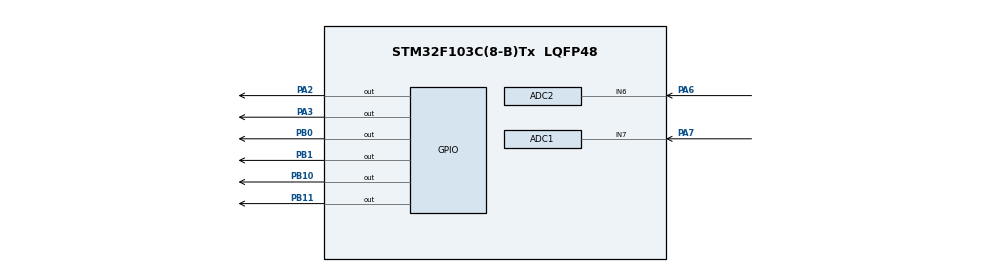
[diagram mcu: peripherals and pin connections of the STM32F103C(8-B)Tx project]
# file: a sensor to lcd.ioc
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ADC1.Channel-0\#ChannelRegularConversion=ADC_CHANNEL_7
ADC1.ContinuousConvMode=ENABLE
ADC1.NbrOfConversionFlag=1
ADC1.Rank-0\#ChannelRegularConversion=1
ADC1.SamplingTime-0\#ChannelRegularConversion=ADC_SAMPLETIME_1CYCLE_5
ADC1.master=1
ADC2.Channel-0\#ChannelRegularConversion=ADC_CHANNEL_6
ADC2.ContinuousConvMode=ENABLE
ADC2.NbrOfConversionFlag=1
ADC2.Rank-0\#ChannelRegularConversion=1
ADC2.SamplingTime-0\#ChannelRegularConversion=ADC_SAMPLETIME_1CYCLE_5
Mcu.Family=STM32F1
Mcu.Name=STM32F103C(8-B)Tx
Mcu.Package=LQFP48
NVIC.PriorityGroup=NVIC_PRIORITYGROUP_4
PA13.Mode=Serial_Wire
PA13.Signal=SYS_JTMS-SWDIO
PA14.Mode=Serial_Wire
PA14.Signal=SYS_JTCK-SWCLK
PA2.GPIO_Speed=GPIO_SPEED_FREQ_HIGH
PA2.Signal=GPIO_Output
PA3.GPIO_Speed=GPIO_SPEED_FREQ_HIGH
PA3.Signal=GPIO_Output
PA6.Signal=ADCx_IN6
PA7.Signal=ADCx_IN7
PB0.GPIO_Speed=GPIO_SPEED_FREQ_HIGH
PB0.Signal=GPIO_Output
PB1.GPIO_Speed=GPIO_SPEED_FREQ_HIGH
PB1.Signal=GPIO_Output
PB10.GPIO_Speed=GPIO_SPEED_FREQ_HIGH
PB10.Signal=GPIO_Output
PB11.GPIO_Speed=GPIO_SPEED_FREQ_HIGH
PB11.Signal=GPIO_Output
ProjectManager.HeapSize=0x200
ProjectManager.StackSize=0x400
ProjectManager.TargetToolchain=STM32CubeIDE
RCC.APB1Freq_Value=8000000
RCC.APB2Freq_Value=8000000
SH.ADCx_IN6.0=ADC2_IN6,IN6
SH.ADCx_IN7.0=ADC1_IN7,IN7
board=custom

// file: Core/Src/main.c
/* USER CODE BEGIN Header */
/**
  ******************************************************************************
  * @file           : main.c
  * @brief          : Main program body
  ******************************************************************************
  * @attention
  *
  * <h2><center>&copy; Copyright (c) 2021 STMicroelectronics.
  * All rights reserved.</center></h2>
  *
  * This software component is licensed by ST under BSD 3-Clause license,
  * the "License"; You may not use this file except in compliance with the
  * License. You may obtain a copy of the License at:
  *                        opensource.org/licenses/BSD-3-Clause
  *
  ******************************************************************************
  */
/* USER CODE END Header */
#include "main.h"
#include "lcd.h"

ADC_HandleTypeDef hadc1;
ADC_HandleTypeDef hadc2;

/* USER CODE BEGIN PV */
uint16_t moisture_value;
uint16_t vibrating_value;
int a=0;
/* USER CODE END PV */

void SystemClock_Config(void);
static void MX_GPIO_Init(void);
static void MX_ADC1_Init(void);
static void MX_ADC2_Init(void);

int main(void)
{

  /* MCU Configuration--------------------------------------------------------*/

  /* Reset of all peripherals, Initializes the Flash interface and the Systick. */
  HAL_Init();

  /* Configure the system clock */
  SystemClock_Config();

  /* Initialize all configured peripherals */
  MX_GPIO_Init();
  MX_ADC1_Init();
  MX_ADC2_Init();
  /* USER CODE BEGIN 2 */
  HAL_ADC_Start(&hadc1);
  HAL_ADC_Start(&hadc2);
  Lcd_PortType ports[] = { GPIOB, GPIOB, GPIOB, GPIOB };
  Lcd_PinType pins[] = {GPIO_PIN_0, GPIO_PIN_1, GPIO_PIN_10, GPIO_PIN_11};
  Lcd_HandleTypeDef lcd;
  lcd = Lcd_create(ports, pins, GPIOA, GPIO_PIN_2, GPIOA, GPIO_PIN_3, LCD_4_BIT_MODE);
  Lcd_cursor(&lcd, 0,2);
  Lcd_string(&lcd, "MOI_SEN:");
  Lcd_cursor(&lcd, 1,2);
  Lcd_string(&lcd, "VIB_SEN:");
  HAL_Delay(500);
  /* USER CODE END 2 */

  /* Infinite loop */
  while (1)
  {
 HAL_ADC_PollForConversion(&hadc1,1000);
 moisture_value=4095-HAL_ADC_GetValue(&hadc1);
 HAL_ADC_PollForConversion(&hadc2,1000);
 vibrating_value =HAL_ADC_GetValue(&hadc2);
 HAL_Delay(100);
 Lcd_cursor(&lcd, 0,10);
 Lcd_int(&lcd, moisture_value);
 Lcd_cursor(&lcd, 1,10);
 Lcd_int(&lcd, vibrating_value);

  }
}

void SystemClock_Config(void)
{
  RCC_OscInitTypeDef RCC_OscInitStruct = {0};
  RCC_ClkInitTypeDef RCC_ClkInitStruct = {0};
  RCC_PeriphCLKInitTypeDef PeriphClkInit = {0};

  /** Initializes the RCC Oscillators according to the specified parameters
  * in the RCC_OscInitTypeDef structure.
  */
  RCC_OscInitStruct.OscillatorType = RCC_OSCILLATORTYPE_HSI;
  RCC_OscInitStruct.HSIState = RCC_HSI_ON;
  RCC_OscInitStruct.HSICalibrationValue = RCC_HSICALIBRATION_DEFAULT;
  RCC_OscInitStruct.PLL.PLLState = RCC_PLL_NONE;
  if (HAL_RCC_OscConfig(&RCC_OscInitStruct) != HAL_OK)
  {
    Error_Handler();
  }
  /** Initializes the CPU, AHB and APB buses clocks
  */
  RCC_ClkInitStruct.ClockType = RCC_CLOCKTYPE_HCLK|RCC_CLOCKTYPE_SYSCLK
                              |RCC_CLOCKTYPE_PCLK1|RCC_CLOCKTYPE_PCLK2;
  RCC_ClkInitStruct.SYSCLKSource = RCC_SYSCLKSOURCE_HSI;
  RCC_ClkInitStruct.AHBCLKDivider = RCC_SYSCLK_DIV1;
  RCC_ClkInitStruct.APB1CLKDivider = RCC_HCLK_DIV1;
  RCC_ClkInitStruct.APB2CLKDivider = RCC_HCLK_DIV1;

  if (HAL_RCC_ClockConfig(&RCC_ClkInitStruct, FLASH_LATENCY_0) != HAL_OK)
  {
    Error_Handler();
  }
  PeriphClkInit.PeriphClockSelection = RCC_PERIPHCLK_ADC;
  PeriphClkInit.AdcClockSelection = RCC_ADCPCLK2_DIV2;
  if (HAL_RCCEx_PeriphCLKConfig(&PeriphClkInit) != HAL_OK)
  {
    Error_Handler();
  }
}

static void MX_ADC1_Init(void)
{

  ADC_ChannelConfTypeDef sConfig = {0};

  /** Common config
  */
  hadc1.Instance = ADC1;
  hadc1.Init.ScanConvMode = ADC_SCAN_DISABLE;
  hadc1.Init.ContinuousConvMode = ENABLE;
  hadc1.Init.DiscontinuousConvMode = DISABLE;
  hadc1.Init.ExternalTrigConv = ADC_SOFTWARE_START;
  hadc1.Init.DataAlign = ADC_DATAALIGN_RIGHT;
  hadc1.Init.NbrOfConversion = 1;
  if (HAL_ADC_Init(&hadc1) != HAL_OK)
  {
    Error_Handler();
  }
  /** Configure Regular Channel
  */
  sConfig.Channel = ADC_CHANNEL_4;
  sConfig.Rank = ADC_REGULAR_RANK_1;
  sConfig.SamplingTime = ADC_SAMPLETIME_1CYCLE_5;
  if (HAL_ADC_ConfigChannel(&hadc1, &sConfig) != HAL_OK)
  {
    Error_Handler();
  }

}

static void MX_ADC2_Init(void)
{

  ADC_ChannelConfTypeDef sConfig = {0};

  /** Common config
  */
  hadc2.Instance = ADC2;
  hadc2.Init.ScanConvMode = ADC_SCAN_DISABLE;
  hadc2.Init.ContinuousConvMode = ENABLE;
  hadc2.Init.DiscontinuousConvMode = DISABLE;
  hadc2.Init.ExternalTrigConv = ADC_SOFTWARE_START;
  hadc2.Init.DataAlign = ADC_DATAALIGN_RIGHT;
  hadc2.Init.NbrOfConversion = 1;
  if (HAL_ADC_Init(&hadc2) != HAL_OK)
  {
    Error_Handler();
  }
  /** Configure Regular Channel
  */
  sConfig.Channel = ADC_CHANNEL_5;
  sConfig.Rank = ADC_REGULAR_RANK_1;
  sConfig.SamplingTime = ADC_SAMPLETIME_1CYCLE_5;
  if (HAL_ADC_ConfigChannel(&hadc2, &sConfig) != HAL_OK)
  {
    Error_Handler();
  }

}

static void MX_GPIO_Init(void)
{
  GPIO_InitTypeDef GPIO_InitStruct = {0};

  /* GPIO Ports Clock Enable */
  __HAL_RCC_GPIOA_CLK_ENABLE();
  __HAL_RCC_GPIOB_CLK_ENABLE();

  /*Configure GPIO pin Output Level */
  HAL_GPIO_WritePin(GPIOA, GPIO_PIN_2|GPIO_PIN_3, GPIO_PIN_RESET);

  /*Configure GPIO pin Output Level */
  HAL_GPIO_WritePin(GPIOB, GPIO_PIN_0|GPIO_PIN_1|GPIO_PIN_10|GPIO_PIN_11
                          |GPIO_PIN_5, GPIO_PIN_RESET);

  /*Configure GPIO pins : PA2 PA3 */
  GPIO_InitStruct.Pin = GPIO_PIN_2|GPIO_PIN_3;
  GPIO_InitStruct.Mode = GPIO_MODE_OUTPUT_PP;
  GPIO_InitStruct.Pull = GPIO_NOPULL;
  GPIO_InitStruct.Speed = GPIO_SPEED_FREQ_HIGH;
  HAL_GPIO_Init(GPIOA, &GPIO_InitStruct);

  /*Configure GPIO pins : PB0 PB1 PB10 PB11
                           PB5 */
  GPIO_InitStruct.Pin = GPIO_PIN_0|GPIO_PIN_1|GPIO_PIN_10|GPIO_PIN_11
                          |GPIO_PIN_5;
  GPIO_InitStruct.Mode = GPIO_MODE_OUTPUT_PP;
  GPIO_InitStruct.Pull = GPIO_NOPULL;
  GPIO_InitStruct.Speed = GPIO_SPEED_FREQ_HIGH;
  HAL_GPIO_Init(GPIOB, &GPIO_InitStruct);

}

void Error_Handler(void)
{
  __disable_irq();
  while (1)
  {
  }
}

/************************ (C) COPYRIGHT STMicroelectronics *****END OF FILE****/
